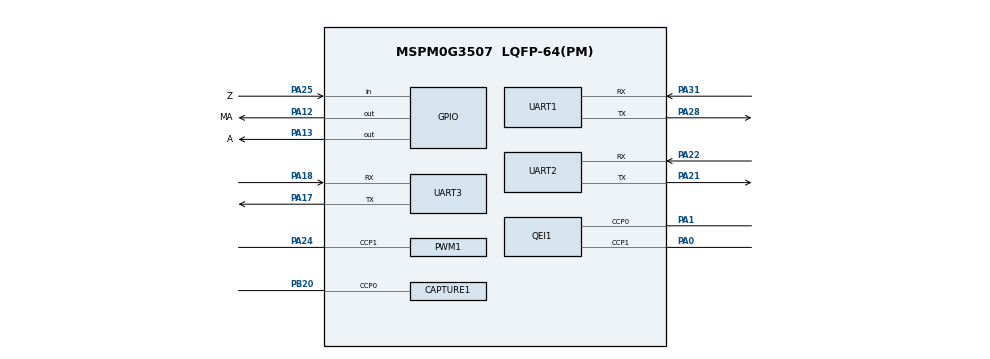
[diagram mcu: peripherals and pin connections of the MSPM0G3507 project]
//@cliArgs --device "MSPM0G350X" --package "LQFP-64(PM)" --part "Default"
//@v2CliArgs --device "MSPM0G3507" --package "LQFP-64(PM)"

/**
 * Import the modules used in this configuration.
 */
const CAPTURE       = scripting.addModule("/ti/driverlib/CAPTURE", {}, false);
const CAPTURE1      = CAPTURE.addInstance();
const GPIO          = scripting.addModule("/ti/driverlib/GPIO", {}, false);
const GPIO1         = GPIO.addInstance();
const GPIO2         = GPIO.addInstance();
const GPIO3         = GPIO.addInstance();
const PWM           = scripting.addModule("/ti/driverlib/PWM", {}, false);
const PWM1          = PWM.addInstance();
const QEI           = scripting.addModule("/ti/driverlib/QEI", {}, false);
const QEI1          = QEI.addInstance();
const SYSCTL        = scripting.addModule("/ti/driverlib/SYSCTL");
const SYSTICK       = scripting.addModule("/ti/driverlib/SYSTICK");
const TIMER         = scripting.addModule("/ti/driverlib/TIMER", {}, false);
const TIMER1        = TIMER.addInstance();
const UART          = scripting.addModule("/ti/driverlib/UART", {}, false);
const UART1         = UART.addInstance();
const UART2         = UART.addInstance();
const UART3         = UART.addInstance();

/**
 * Write custom configuration values to the imported modules.
 */

/* 时钟: SYSOSC(32MHz) → SYSPLL ×5÷2 → 80MHz MCLK */
SYSCTL.forceDefaultClkConfig = true;
SYSCTL.clockTreeEn           = true;
/* SYSPLL 配置: 32MHz * 5 / 2 = 80MHz */
const divider7       = system.clockTree["PLL_PDIV"];
divider7.divideValue = 2;
const divider9       = system.clockTree["UDIV"];
divider9.divideValue = 2;
const gate7          = system.clockTree["MFCLKGATE"];
gate7.enable         = true;
const multiplier2         = system.clockTree["PLL_QDIV"];
multiplier2.multiplyValue = 5;
const mux8       = system.clockTree["HSCLKMUX"];
mux8.inputSelect = "HSCLKMUX_SYSPLL2X";

/* UART0: PA28(TX) / PA31(RX), 115200bps, 需外接 USB-TTL 模块 */
UART1.$name                    = "UART_0";
UART1.targetBaudRate           = 115200;
UART1.enableFIFO               = true;
UART1.peripheral.rxPin.$assign = "PA31";
UART1.peripheral.txPin.$assign = "PA28";
UART1.txPinConfig.$name        = "ti_driverlib_gpio_GPIOPinGeneric2";
UART1.rxPinConfig.$name        = "ti_driverlib_gpio_GPIOPinGeneric3";

/* UART2: PA21(TX) / PA22(RX), 115200bps, MaixCam 双向通信 */
UART2.$name                    = "UART_2";
UART2.targetBaudRate           = 115200;
UART2.enableFIFO               = true;
UART2.peripheral.rxPin.$assign = "PA22";
UART2.peripheral.txPin.$assign = "PA21";
UART2.txPinConfig.$name        = "UART2_TX_PIN_CONFIG";
UART2.rxPinConfig.$name        = "UART2_RX_PIN_CONFIG";

/* UART1: PA18(TX) / PA17(RX), 115200bps, 主控通信 */
UART3.$name                    = "UART_1";
UART3.targetBaudRate           = 115200;
UART3.enableFIFO               = true;
UART3.peripheral.rxPin.$assign = "PA18";
UART3.peripheral.txPin.$assign = "PA17";
UART3.txPinConfig.$name        = "UART1_TX_PIN_CONFIG";
UART3.rxPinConfig.$name        = "UART1_RX_PIN_CONFIG";

/* PWM: TIMA1 CCP1, PA24, 1MHz 时钟, STEP 脉冲输出 */
PWM1.$name                      = "PWM_0";
PWM1.clockPrescale              = 80;
PWM1.ccIndex                    = [1];
PWM1.peripheral.ccp1Pin.$assign = "PA24";
PWM1.ccp1PinConfig.$name        = "ti_driverlib_gpio_GPIOPinGeneric1";
PWM1.PWM_CHANNEL_1.$name        = "ti_driverlib_pwm_PWMTimerCC1";

/* QEI: TIMG8, PA1(A相) / PA0(B相), 编码器正交解码 */
QEI1.$name                      = "QEI_0";
QEI1.timerStartTimer            = true;
QEI1.peripheral.$assign         = "TIMG8";
QEI1.peripheral.ccp0Pin.$assign = "PA1";
QEI1.peripheral.ccp1Pin.$assign = "PA0";
QEI1.ccp0PinConfig.$name        = "QEI_A_PIN_CONFIG";
QEI1.ccp1PinConfig.$name        = "QEI_B_PIN_CONFIG";

/* CAPTURE: TIMG12 CCP0, PB20, 编码器 PWM 脉宽+周期捕获 */
CAPTURE1.$name                              = "ENCODER_PWM";
CAPTURE1.captMode                           = "COMBINED";
CAPTURE1.timerPeriod                        = "50 ms";
CAPTURE1.timerStartTimer                    = true;
CAPTURE1.interrupts                         = ["CC0_DN","CC1_DN"];
CAPTURE1.peripheral.$assign                 = "TIMG12";
CAPTURE1.peripheral.ccp0Pin.$assign         = "PB20";
CAPTURE1.ccp0PinConfig.hideOutputInversion  = scripting.forceWrite(false);
CAPTURE1.ccp0PinConfig.onlyInternalResistor = scripting.forceWrite(false);
CAPTURE1.ccp0PinConfig.passedPeripheralType = scripting.forceWrite("Digital");
CAPTURE1.ccp0PinConfig.$name                = "ENCODER_PWM_PIN_CONFIG";

/* TIMER: TIMG0, 5ms 周期中断, 闭环控制定时器 */
TIMER1.$name              = "TIMER_0";
TIMER1.timerClkPrescale   = 32;
TIMER1.timerMode          = "PERIODIC";
TIMER1.timerStartTimer    = true;
TIMER1.interrupts         = ["ZERO"];
TIMER1.timerPeriod        = "5 ms";
TIMER1.peripheral.$assign = "TIMG0";

/* GPIO: PA13 - DIR 方向控制 (推挽输出) */
GPIO1.port                          = "PORTA";
GPIO1.$name                         = "DIR";
GPIO1.associatedPins[0].$name       = "A";
GPIO1.associatedPins[0].pin.$assign = "PA13";

/* GPIO: PA12 - EN 使能 (推挽输出, 高有效) */
GPIO2.$name                         = "EN";
GPIO2.associatedPins[0].$name       = "MA";
GPIO2.associatedPins[0].pin.$assign = "PA12";

/* GPIO: PA25 - 编码器 Z 相 (输入, 下拉, 上升沿中断) */
GPIO3.$name                              = "ENCODER_Z";
GPIO3.associatedPins[0].$name            = "Z";
GPIO3.associatedPins[0].direction        = "INPUT";
GPIO3.associatedPins[0].internalResistor = "PULL_DOWN";
GPIO3.associatedPins[0].interruptEn      = true;
GPIO3.associatedPins[0].polarity         = "RISE";
GPIO3.associatedPins[0].pin.$assign      = "PA25";

/* SysTick: 使能, 用于 delay_ms/delay_us */
SYSTICK.periodEnable  = true;
SYSTICK.systickEnable = true;
SYSTICK.period        = 16777216;

/**
 * Pinmux solution for unlocked pins/peripherals.
 */
const Board = scripting.addModule("/ti/driverlib/Board", {}, false);
Board.peripheral.$suggestSolution          = "DEBUGSS";
Board.peripheral.swclkPin.$suggestSolution = "PA20";
Board.peripheral.swdioPin.$suggestSolution = "PA19";
PWM1.peripheral.$suggestSolution           = "TIMA1";
UART1.peripheral.$suggestSolution          = "UART0";
UART2.peripheral.$suggestSolution          = "UART2";
UART3.peripheral.$suggestSolution          = "UART1";
